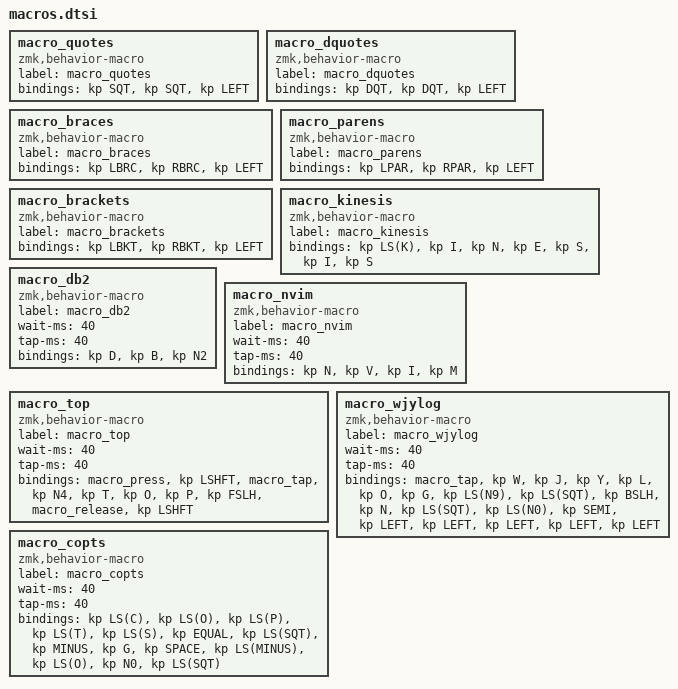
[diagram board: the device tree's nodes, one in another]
  macro_quotes: macro_quotes {
    compatible = "zmk,behavior-macro";
    label = "macro_quotes";
    #binding-cells = <0>;
    bindings = <&kp SQT>, <&kp SQT>, <&kp LEFT>;
  };
  macro_dquotes: macro_dquotes {
    compatible = "zmk,behavior-macro";
    label = "macro_dquotes";
    #binding-cells = <0>;
    bindings = <&kp DQT>, <&kp DQT>, <&kp LEFT>;
  };
  macro_braces: macro_braces {
    compatible = "zmk,behavior-macro";
    label = "macro_braces";
    #binding-cells = <0>;
    bindings = <&kp LBRC>, <&kp RBRC>, <&kp LEFT>;
  };
  macro_parens: macro_parens {
    compatible = "zmk,behavior-macro";
    label = "macro_parens";
    #binding-cells = <0>;
    bindings = <&kp LPAR>, <&kp RPAR>, <&kp LEFT>;
  };
  macro_brackets: macro_brackets {
    compatible = "zmk,behavior-macro";
    label = "macro_brackets";
    #binding-cells = <0>;
    bindings = <&kp LBKT>, <&kp RBKT>, <&kp LEFT>;
  };
  macro_kinesis: macro_kinesis {
    compatible = "zmk,behavior-macro";
    label = "macro_kinesis";
    #binding-cells = <0>;
    bindings = <&kp LS(K)>, <&kp I>, <&kp N>, <&kp E>, <&kp S>, <&kp I>, <&kp S>;
  };
  macro_db2: macro_db2 {
    compatible = "zmk,behavior-macro";
    label = "macro_db2";
    #binding-cells = <0>;
    wait-ms = <40>;
    tap-ms = <40>;
    bindings = <&kp D>, <&kp B>, <&kp N2>;
  };
  macro_nvim: macro_nvim {
    compatible = "zmk,behavior-macro";
    label = "macro_nvim";
    #binding-cells = <0>;
    wait-ms = <40>;
    tap-ms = <40>;
    bindings = <&kp N>, <&kp V>, <&kp I>, <&kp M>;
  };
  macro_top: macro_top {
    compatible = "zmk,behavior-macro";
    label = "macro_top";
    #binding-cells = <0>;
    wait-ms = <40>;
    tap-ms = <40>;
    bindings
      = <&macro_press &kp LSHFT>
      , <&macro_tap &kp N4 &kp T &kp O &kp P &kp FSLH>
      , <&macro_release &kp LSHFT>
      ;
  };
  macro_wjylog: macro_wjylog {
    compatible = "zmk,behavior-macro";
    label = "macro_wjylog";
    #binding-cells = <0>;
    wait-ms = <40>;
    tap-ms = <40>;
    bindings
      = <&macro_tap &kp W &kp J &kp Y &kp L &kp O &kp G>
      , <&kp LS(N9)>, <&kp LS(SQT)>, <&kp BSLH>, <&kp N>, <&kp LS(SQT)>, <&kp LS(N0)>, <&kp SEMI>
      , <&kp LEFT>, <&kp LEFT>, <&kp LEFT>, <&kp LEFT>, <&kp LEFT>
      ;
  };
  macro_copts: macro_copts {
    compatible = "zmk,behavior-macro";
    label = "macro_copts";
    #binding-cells = <0>;
    wait-ms = <40>;
    tap-ms = <40>;
    bindings
      = <&kp LS(C)>, <&kp LS(O)>, <&kp LS(P)>, <&kp LS(T)>, <&kp LS(S)>
      , <&kp EQUAL>, <&kp LS(SQT)>, <&kp MINUS>, <&kp G>, <&kp SPACE>, <&kp LS(MINUS)>, <&kp LS(O)>, <&kp N0>, <&kp LS(SQT)>
      ;
  };
//      , <&kp SPACE>, <&kp B>, <&kp L>, <&kp D>
